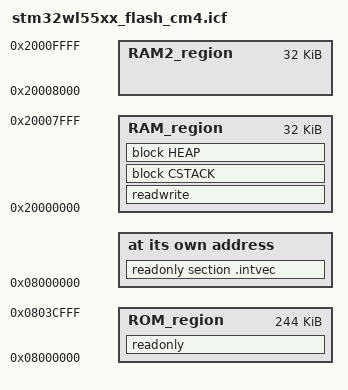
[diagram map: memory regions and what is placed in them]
/*###ICF### Section handled by ICF editor, don't touch! ****/
/*-Editor annotation file-*/
/* IcfEditorFile="$TOOLKIT_DIR$\config\ide\IcfEditor\cortex_v1_0.xml" */
/*-Specials-*/
define symbol __ICFEDIT_intvec_start__ = 0x08000000;

/*-Memory Regions-*/
/***** FLASH *****/
define symbol __ICFEDIT_region_ROM_start__    = 0x08000000;
define symbol __ICFEDIT_region_ROM_end__      = 0x0803CFFF;
/***** Non-backup SRAM1 *****/
define symbol __ICFEDIT_region_RAM_start__    = 0x20000000;
define symbol __ICFEDIT_region_RAM_end__      = 0x20007FFF;
/***** Backup SRAM2 *****/
define symbol __ICFEDIT_region_RAM2_start__   = 0x20008000;
define symbol __ICFEDIT_region_RAM2_end__     = 0x2000FFFF;

/* KMS download region */
/* Area reserved to download blob image to import: 4 kbytes */
define exported symbol __ICFEDIT_KMS_DownArea_start__ = 0x0803D000;
define exported symbol __ICFEDIT_KMS_DownArea_end__   = 0x0803DFFF;

/* KMS Data Storage (NVM) region */
/* KMS Data Storage need for 2 images : 4 kbytes * 2 ==> 8 kbytes */
define exported symbol __ICFEDIT_KMS_DataStorage_start__ = 0x0803E000;
define exported symbol __ICFEDIT_KMS_DataStorage_end__   = 0x0803FFFF;

/*-Sizes-*/
define symbol __ICFEDIT_size_cstack__ = 0xC00;
define symbol __ICFEDIT_size_heap__   = 0xC00;
/**** End of ICF editor section. ###ICF###*/


define memory mem with size = 4G;
define region ROM_region      = mem:[from __ICFEDIT_region_ROM_start__   to __ICFEDIT_region_ROM_end__];
define region RAM_region      = mem:[from __ICFEDIT_region_RAM_start__   to __ICFEDIT_region_RAM_end__];
define region RAM2_region     = mem:[from __ICFEDIT_region_RAM2_start__  to __ICFEDIT_region_RAM2_end__];

define block CSTACK    with alignment = 8, size = __ICFEDIT_size_cstack__   { };
define block HEAP      with alignment = 8, size = __ICFEDIT_size_heap__     { };

initialize by copy { readwrite };
do not initialize  { section .noinit };

place at address mem:__ICFEDIT_intvec_start__ { readonly section .intvec };

place in ROM_region   { readonly };
place in RAM_region   { readwrite,
                        block CSTACK, block HEAP };
place in RAM2_region  { };
